# PY32F003xx register map
Vendor: Puya; Series: PY32F0; File version: 1.0.0
CPU: CM0+ r0p1, little endian, no MPU, no FPU, 4 interrupt priority bits
Registers are 32-bit, read-write, reset 0x0 unless marked. A register's access mark holds for its fields unless they carry their own. Offsets are from the block's base; [hi:lo] are bit positions; {n}, {i} and the like mark numbered series; 'fields as' and 'values as' point back to an identical list.

## SYSCFG — System configuration controller
Base 0x40010000
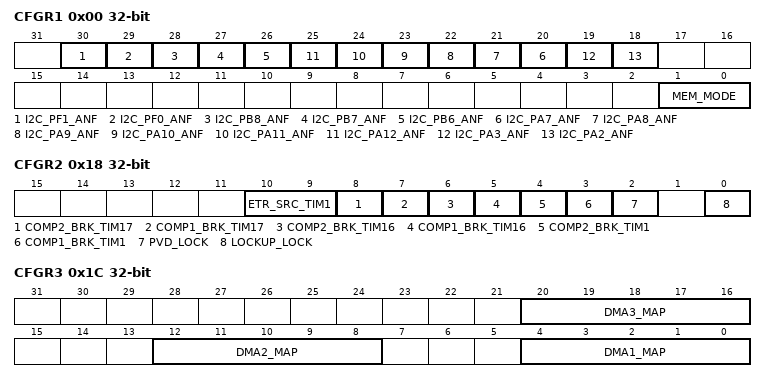
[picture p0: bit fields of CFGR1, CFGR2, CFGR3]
0x00 CFGR1 — SYSCFG configuration register 1
  [30] I2C_PF1_ANF — Analog filter enable control driving capability activation bits PF1
    0=Standard (Pin operate in standard mode); 1=AnalogFilter (I2C Analog filter enabled on pin)
  [29] I2C_PF0_ANF — Analog filter enable control driving capability activation bits PF0
    values as I2C_PF1_ANF
  [28] I2C_PB8_ANF — Analog filter enable control driving capability activation bits PB8
    values as I2C_PF1_ANF
  [27] I2C_PB7_ANF — Analog filter enable control driving capability activation bits PB7
    values as I2C_PF1_ANF
  [26] I2C_PB6_ANF — Analog filter enable control driving capability activation bits PB6
    values as I2C_PF1_ANF
  [n+13] I2C_PA{n}_ANF (n=7..12) — Analog filter enable control driving capability activation bits PA{n}
    values as I2C_PF1_ANF
  [19] I2C_PA3_ANF — Analog filter enable control driving capability activation bits PA3
    values as I2C_PF1_ANF
  [18] I2C_PA2_ANF — Analog filter enable control driving capability activation bits PA2
    values as I2C_PF1_ANF
  [1:0] MEM_MODE — Memory mapping selection bits
    0=Main Flash memory mapped at 0x0000_0000; 1=System Flash memory mapped at 0x0000_0000; 2=MainFlash2 (Main Flash memory mapped at 0x0000_0000); 3=SRAM (Embedded SRAM mapped at 0x0000_0000)
0x18 CFGR2 — SYSCFG configuration register 2
  [10:9] ETR_SRC_TIM1 — TIM1 ETR source selection
    0=GPIO (TIM1_ETR is connected to GPIO); 1=COMP1 (TIM1_ETR is connected to COMP1); 2=COMP2 (TIM1_ETR is connected to COMP2); 3=ADC (TIM1_ETR is connected to ADC)
  [8] COMP2_BRK_TIM17 — COMP2 is enable to input of TIM17 break
    0=Disconnected (COMP? output not connect to TIM? Break input); 1=Connected (COMP? output connected to TIM? Break input)
  [7] COMP1_BRK_TIM17 — COMP1 is enable to input of TIM17 break
    values as COMP2_BRK_TIM17
  [6] COMP2_BRK_TIM16 — COMP2 is enable to input of TIM16 break
    values as COMP2_BRK_TIM17
  [5] COMP1_BRK_TIM16 — COMP1 is enable to input of TIM16 break
    values as COMP2_BRK_TIM17
  [4] COMP2_BRK_TIM1 — COMP2 is enable to input of TIM1 break
    values as COMP2_BRK_TIM17
  [3] COMP1_BRK_TIM1 — COMP1 is enable to input of TIM1 break
    values as COMP2_BRK_TIM17
  [2] PVD_LOCK — PVD lock enable bit
    0=Disconnected (PVD LOCKUP output disconnected from TIM1/16/17 Break input); 1=Connected (PVD LOCKUP output connected to TIM1/16/17 Break input)
  [0] LOCKUP_LOCK — Cortex-M0+ LOCKUP bit enable bit
    0=Disconnected (Cortex-M0+ LOCKUP output disconnected from TIM1/16/17 Break input); 1=Connected (Cortex-M0+ LOCKUP output connected to TIM1/16/17 Break input)
0x1C CFGR3 — SYSCFG configuration register 3
  [all] fields
    0=ADC (ADC DMA requests mapped on DMA?); 1=SPI1_TX (SPI1_TX DMA requests mapped on DMA?); 2=SPI1_RX (SPI1_RX DMA requests mapped on DMA?); 5=USART1_TX (USART1_TX DMA requests mapped on DMA?); 6=USART1_RX (USART1_RX DMA requests mapped on DMA?); 7=USART2_TX (USART2_TX DMA requests mapped on DMA?); 8=USART2_RX (USART2_RX DMA requests mapped on DMA?); 9=I2C_TX (I2C_TX DMA requests mapped on DMA?); 10=I2C_RX (I2C_RX DMA requests mapped on DMA?); {v}=TIM1_CH{v-10} (TIM1_CH{v-10} DMA requests mapped on DMA?) (v=11..14); 15=TIM1_COM (TIM1_COM DMA requests mapped on DMA?); 16=TIM1_UP (TIM1_UP DMA requests mapped on DMA?); 17=TIM1_TRIG (TIM1_TRIG DMA requests mapped on DMA?); 18=TIM3_CH1 (TIM3_CH1 DMA requests mapped on DMA?); 19=TIM3_CH3 (TIM3_CH3 DMA requests mapped on DMA?); 20=TIM3_CH4 (TIM3_CH4 DMA requests mapped on DMA?); 21=TIM3_TRG (TIM3_TRG DMA requests mapped on DMA?); 22=TIM3_UP (TIM3_UP DMA requests mapped on DMA?); 24=TIM16_CH1 (TIM16_CH1 DMA requests mapped on DMA?); 25=TIM16_UP (TIM16_UP DMA requests mapped on DMA?); 26=TIM17_CH1 (TIM17_CH1 DMA requests mapped on DMA?); 27=TIM17_UP (TIM17_UP DMA requests mapped on DMA?)
  [20:16] DMA3_MAP — DMA channel3 requeset selection
  [12:8] DMA2_MAP — DMA channel2 requeset selection
  [4:0] DMA1_MAP — DMA channel1 requeset selection
